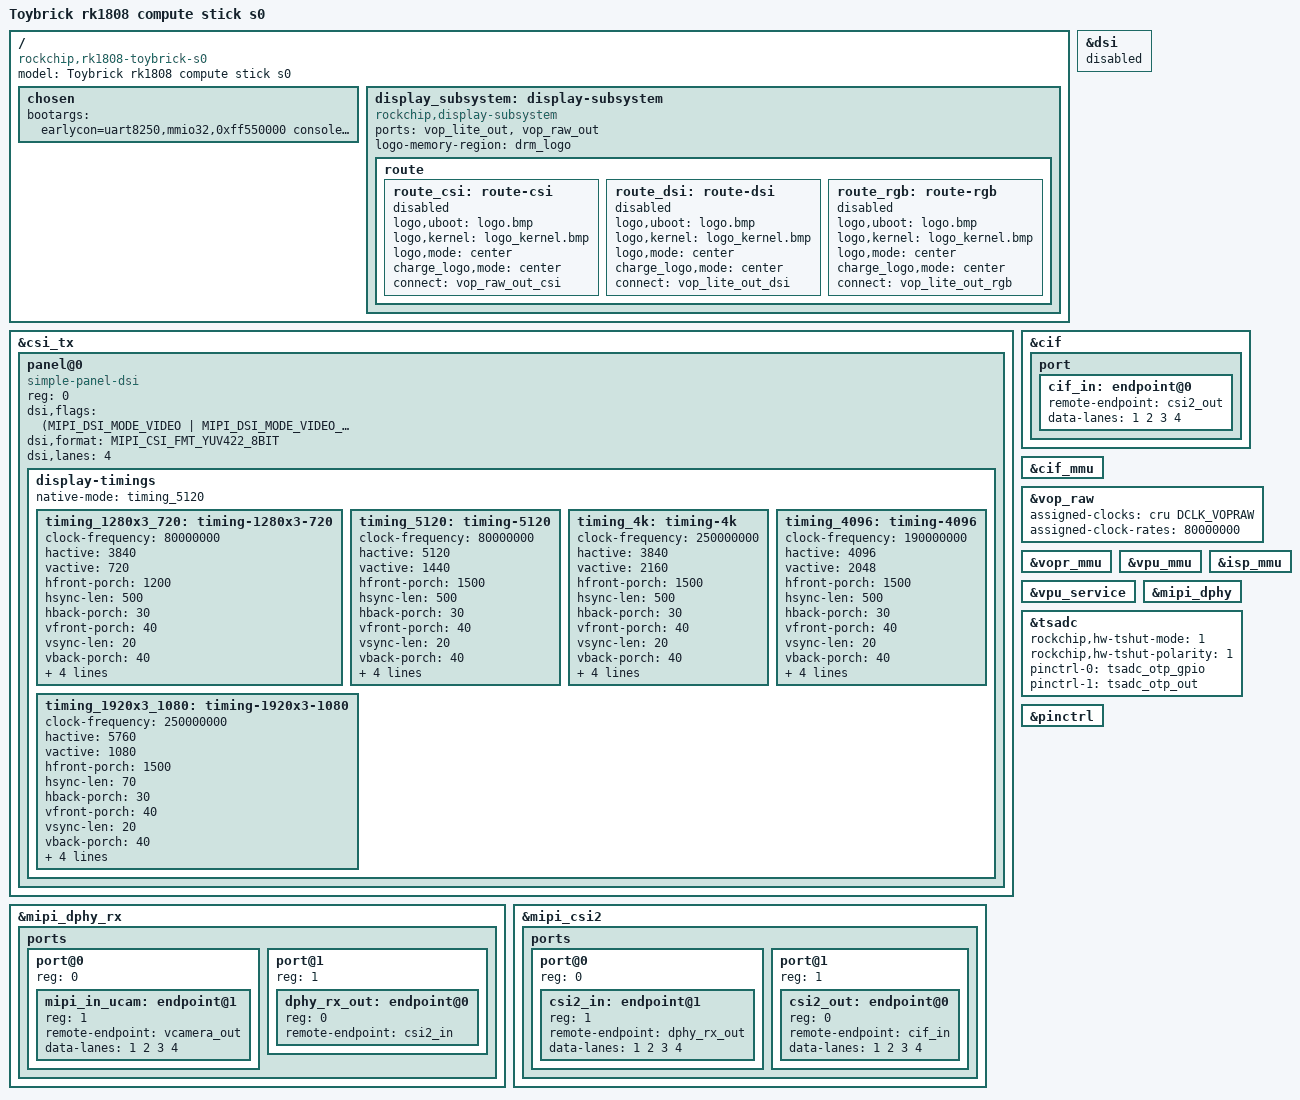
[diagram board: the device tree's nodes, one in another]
// SPDX-License-Identifier: (GPL-2.0+ OR MIT)
/*
 * Copyright (c) 2018 Fuzhou Rockchip Electronics Co., Ltd
 */

/dts-v1/;
#include "rk1808-toybrick-prox.dtsi"

/ {
	model = "Toybrick rk1808 compute stick s0";
	compatible = "rockchip,rk1808-toybrick-s0", "rockchip,rk1808";

	chosen {
		bootargs = "earlycon=uart8250,mmio32,0xff550000 console=ttyFIQ0 swiotlb=1 coherent_pool=1m swiotlb=1 kpti=0";
	};
	
	display_subsystem: display-subsystem {
		compatible = "rockchip,display-subsystem";
		ports = <&vop_lite_out>, <&vop_raw_out>;
		logo-memory-region = <&drm_logo>;
		status = "okay";

		route {
			route_csi: route-csi {
				status = "disabled";
				logo,uboot = "logo.bmp";
				logo,kernel = "logo_kernel.bmp";
				logo,mode = "center";
				charge_logo,mode = "center";
				connect = <&vop_raw_out_csi>;
			};

			route_dsi: route-dsi {
				status = "disabled";
				logo,uboot = "logo.bmp";
				logo,kernel = "logo_kernel.bmp";
				logo,mode = "center";
				charge_logo,mode = "center";
				connect = <&vop_lite_out_dsi>;
			};

			route_rgb: route-rgb {
				status = "disabled";
				logo,uboot = "logo.bmp";
				logo,kernel = "logo_kernel.bmp";
				logo,mode = "center";
				charge_logo,mode = "center";
				connect = <&vop_lite_out_rgb>;
			};
		};
	};
};

&dsi {
	status = "disabled";
};

&csi_tx {
	status = "okay";

	panel@0 {
		compatible = "simple-panel-dsi";
		reg = <0>;
		dsi,flags = <(MIPI_DSI_MODE_VIDEO | MIPI_DSI_MODE_VIDEO_BURST |
			      MIPI_DSI_MODE_LPM | MIPI_DSI_MODE_EOT_PACKET |
			      MIPI_DSI_CLOCK_NON_CONTINUOUS)>;
		dsi,format = <MIPI_CSI_FMT_YUV422_8BIT>;
		dsi,lanes = <4>;

		display-timings {
			native-mode = <&timing_5120>;

			timing_1280x3_720: timing-1280x3-720 {
				clock-frequency = <80000000>;
				hactive = <3840>;
				vactive = <720>;
				hfront-porch = <1200>;
				hsync-len = <500>;
				hback-porch = <30>;
				vfront-porch = <40>;
				vsync-len = <20>;
				vback-porch = <40>;
				hsync-active = <0>;
				vsync-active = <0>;
				de-active = <0>;
				pixelclk-active = <0>;
			};

			timing_5120: timing-5120 {
				clock-frequency = <80000000>;
				hactive = <5120>;
				vactive = <1440>;
				hfront-porch = <1500>;
				hsync-len = <500>;
				hback-porch = <30>;
				vfront-porch = <40>;
				vsync-len = <20>;
				vback-porch = <40>;
				hsync-active = <0>;
				vsync-active = <0>;
				de-active = <0>;
				pixelclk-active = <0>;
			 };

			timing_4k: timing-4k {
				clock-frequency = <250000000>;
				hactive = <3840>;
				vactive = <2160>;
				hfront-porch = <1500>;
				hsync-len = <500>;
				hback-porch = <30>;
				vfront-porch = <40>;
				vsync-len = <20>;
				vback-porch = <40>;
				hsync-active = <0>;
				vsync-active = <0>;
				de-active = <0>;
				pixelclk-active = <0>;
			};
			timing_4096: timing-4096 {
				clock-frequency = <190000000>;
				hactive = <4096>;
				vactive = <2048>;
				hfront-porch = <1500>;
				hsync-len = <500>;
				hback-porch = <30>;
				vfront-porch = <40>;
				vsync-len = <20>;
				vback-porch = <40>;
				hsync-active = <0>;
				vsync-active = <0>;
				de-active = <0>;
				pixelclk-active = <0>;
			};
			timing_1920x3_1080: timing-1920x3-1080 {
				clock-frequency = <250000000>;
				hactive = <5760>;
				vactive = <1080>;
				hfront-porch = <1500>;
				hsync-len = <70>;
				hback-porch = <30>;
				vfront-porch = <40>;
				vsync-len = <20>;
				vback-porch = <40>;
				hsync-active = <0>;
				vsync-active = <0>;
				de-active = <0>;
				pixelclk-active = <0>;
			};
		};
	};
};

&mipi_dphy_rx {
	status = "okay";

	ports {
		#address-cells = <1>;
		#size-cells = <0>;

		port@0 {
			reg = <0>;
			#address-cells = <1>;
			#size-cells = <0>;

			mipi_in_ucam: endpoint@1 {
				reg = <1>;
				remote-endpoint = <&vcamera_out>;
				data-lanes = <1 2 3 4>;
			};
		};

		port@1 {
			reg = <1>;
			#address-cells = <1>;
			#size-cells = <0>;

			dphy_rx_out: endpoint@0 {
				reg = <0>;
				remote-endpoint = <&csi2_in>;
			};
		};
	};
};

&mipi_csi2 {
	status = "okay";

	ports {
		#address-cells = <1>;
		#size-cells = <0>;

		port@0 {
			reg = <0>;
			#address-cells = <1>;
			#size-cells = <0>;

			csi2_in: endpoint@1 {
				reg = <1>;
				remote-endpoint = <&dphy_rx_out>;
				data-lanes = <1 2 3 4>;
			};
		};

		port@1 {
			reg = <1>;
			#address-cells = <1>;
			#size-cells = <0>;

			csi2_out: endpoint@0 {
				reg = <0>;
				remote-endpoint = <&cif_in>;
				data-lanes = <1 2 3 4>;
			};
		};
	};
};

&cif {
	status = "okay";

	port {
		cif_in: endpoint@0 {
			remote-endpoint = <&csi2_out>;
			data-lanes = <1 2 3 4>;
		};
	};
};

&cif_mmu {
	status = "okay";
};

&display_subsystem {
	status = "okay";
};

&vop_raw {
	status = "okay";
	assigned-clocks = <&cru DCLK_VOPRAW>;
	assigned-clock-rates = <80000000>;
};

&vopr_mmu {
	status = "okay";
};

&vpu_mmu {
	status = "okay";
};

&vpu_service {
	status = "okay";
};

&isp_mmu {
	status = "okay";
};

&mipi_dphy {
	status = "okay";
};

&tsadc {
	rockchip,hw-tshut-mode = <1>; /* tshut mode 0:CRU 1:GPIO */
	rockchip,hw-tshut-polarity = <1>; /* tshut polarity 0:LOW 1:HIGH */
	pinctrl-names = "init", "default";
	pinctrl-0 = <&tsadc_otp_gpio>;
	pinctrl-1 = <&tsadc_otp_out>;
	status = "okay";
};

&pinctrl {
        pinctrl-names = "default";
};

